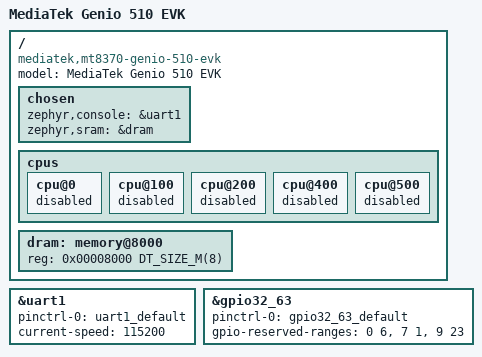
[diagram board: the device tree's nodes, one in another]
/*
 * Copyright (c) 2026 MediaTek Inc.
 *
 * SPDX-License-Identifier: Apache-2.0
 */

/dts-v1/;

#include <mem.h>
#include <mediatek/mt8188.dtsi>

#include "mt8370_genio_510_evk-pinctrl.dtsi"

/ {
	model = "MediaTek Genio 510 EVK";
	compatible = "mediatek,mt8370-genio-510-evk";

	chosen {
		zephyr,console = &uart1;
		zephyr,sram = &dram;
	};

	/*
	 * Zephyr is handed a single A55 core and the memory window below by the
	 * hypervisor; the remaining cores and memory stay with the host.
	 *
	 * MT8390 has six A55 cores and MT8370 four, so cpu@400 and cpu@500 are
	 * absent on the latter; disabling them here covers both parts.
	 */
	cpus {
		cpu@0 {
			status = "disabled";
		};

		cpu@100 {
			status = "disabled";
		};

		cpu@200 {
			status = "disabled";
		};

		cpu@400 {
			status = "disabled";
		};

		cpu@500 {
			status = "disabled";
		};
	};

	dram: memory@8000 {
		reg = <0x00008000 DT_SIZE_M(8)>;
	};
};

&uart1 {
	pinctrl-0 = <&uart1_default>;
	pinctrl-names = "default";
	current-speed = <115200>;
	status = "okay";
};

/*
 * Bank 1 covers GPIO 32 to 63, of which the hypervisor hands this cell only
 * GPIO 38 and 40, which are pins 6 and 8 of the bank.  Every other pin of the
 * bank belongs to the host, so it is reserved here: touching one would reach a
 * pad outside this cell.
 *
 * The remaining five banks stay disabled for the same reason.
 */
&gpio32_63 {
	pinctrl-0 = <&gpio32_63_default>;
	pinctrl-names = "default";
	gpio-reserved-ranges = <0 6>, <7 1>, <9 23>;
	status = "okay";
};
